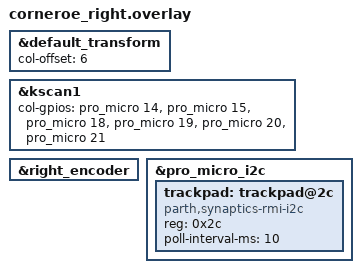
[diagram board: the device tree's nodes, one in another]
/*
 * Copyright (c) 2020 Pete Johanson
 *
 * SPDX-License-Identifier: MIT
 */

#include "corneroe.dtsi"

&default_transform {
    col-offset = <6>;
};

&kscan1 {
    col-gpios
        = <&pro_micro 14 GPIO_ACTIVE_HIGH>
        , <&pro_micro 15 GPIO_ACTIVE_HIGH>
        , <&pro_micro 18 GPIO_ACTIVE_HIGH>
        , <&pro_micro 19 GPIO_ACTIVE_HIGH>
        , <&pro_micro 20 GPIO_ACTIVE_HIGH>
        , <&pro_micro 21 GPIO_ACTIVE_HIGH>
        ;
};

&right_encoder {
    status = "okay";
};

&pro_micro_i2c {
    status = "okay";

    trackpad: trackpad@2c {
        compatible = "parth,synaptics-rmi-i2c";
        reg = <0x2c>;
        poll-interval-ms = <10>;
    };
};
